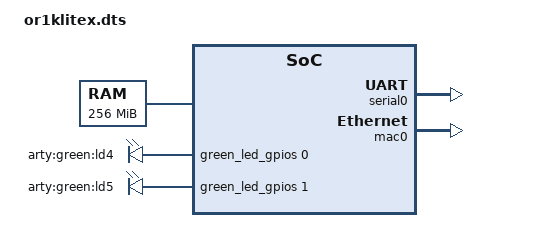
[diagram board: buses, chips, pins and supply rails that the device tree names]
/dts-v1/;

#include <dt-bindings/gpio/gpio.h>
#include <dt-bindings/litex.h>

/ {
	compatible = "opencores,or1ksim";
	#address-cells = <1>;
	#size-cells = <1>;
	interrupt-parent = <&pic>;

	aliases {
		uart0 = &serial0;
	};

	chosen {
		bootargs = "earlycon";
		stdout-path = "uart0:115200";
	};

	memory@0 {
		device_type = "memory";
		reg = <0x40000000 0x10000000>;
	};

	cpus {
		#address-cells = <1>;
		#size-cells = <0>;
		cpu@0 {
			compatible = "opencores,or1200-rtlsvn481";
			reg = <0>;
			clock-frequency = <100000000>;
		};
	};

	pic: pic {
		compatible = "opencores,or1k-pic";
		#interrupt-cells = <1>;
		interrupt-controller;
	};

	serial0: serial@e0001800 {
		device_type = "serial";
		compatible = "litex,litex-uart";
		reg = <CSR_UART_BASE 0x100>;
		interrupts = <2>;
	};

	mac0: mac@e0007800 {
		compatible = "litex,liteeth";
		reg = <CSR_ETHMAC_BASE 0x7c
			CSR_ETHPHY_BASE 0x0a
			ETHMAC_BASE 0x2000>;
		interrupts = <3>;
		tx-fifo-depth = <2>;
		rx-fifo-depth = <2>;
        };

	leds {
		compatible = "gpio-leds";

		ld4 {
			label = "arty:green:ld4";
			linux,default-trigger = "heartbeat";
			gpios = <&green_led_gpios 0 GPIO_ACTIVE_HIGH>;
		};

		ld5 {
			label = "arty:green:ld5";
			gpios = <&green_led_gpios 1 GPIO_ACTIVE_HIGH>;
			panic-indicator;
		};
	};

	green_led_gpios: gpio@e0006800 {
		compatible = "wd,mbl-gpio", "basic-mmio-gpio";
		status = "disabled";
		reg = <0xe0006800 0x1>;
		reg-names = "dat";

		gpio-controller;
		#gpio-cells = <2>;
		gpio-line-names = "ld4", "ld5", "ld6", "ld7", "", "", "", "";
	};
};
